# CH32X035 register map
Vendor: WCH Ltd.; File version: 1.2
Registers are 32-bit, read-write, reset 0x0 unless marked. A register's access mark holds for its fields unless they carry their own. Offsets are from the block's base; [hi:lo] are bit positions.

## IWDG — Independent watchdog
Base 0x40003000
0x00 CTLR 16-bit wo — Key register (IWDG_CTLR)
  [15:0] KEY — Key value
0x04 PSCR 16-bit — Prescaler register (IWDG_PSCR)
  [2:0] PR — Prescaler divider
0x08 RLDR 16-bit reset 0xFFF — Reload register (IWDG_RLDR)
  [11:0] RL — Watchdog counter reload value
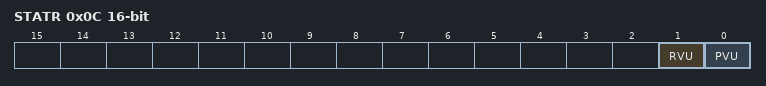
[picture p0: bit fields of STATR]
0x0C STATR 16-bit ro — Status register (IWDG_SR)
  [1] RVU — Watchdog counter reload value update
  [0] PVU — Watchdog prescaler value update

## WWDG — Window watchdog
Base 0x40002C00
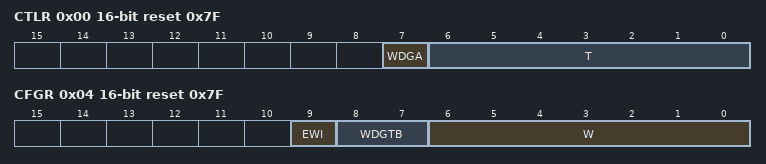
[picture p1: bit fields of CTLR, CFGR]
0x00 CTLR 16-bit reset 0x7F — Control register (WWDG_CR)
  [7] WDGA — Activation bit
  [6:0] T — 7-bit counter (MSB to LSB)
0x04 CFGR 16-bit access per field reset 0x7F — Configuration register (WWDG_CFR)
  [9] EWI read/set — Early Wakeup Interrupt
  [8:7] WDGTB rw — Timer Base
  [6:0] W rw — 7-bit window value
0x08 STATR 16-bit read/clear — Status register (WWDG_SR)
  [0] EWIF — Early Wakeup Interrupt Flag

## TIM3 — General purpose timer
Base 0x40000400
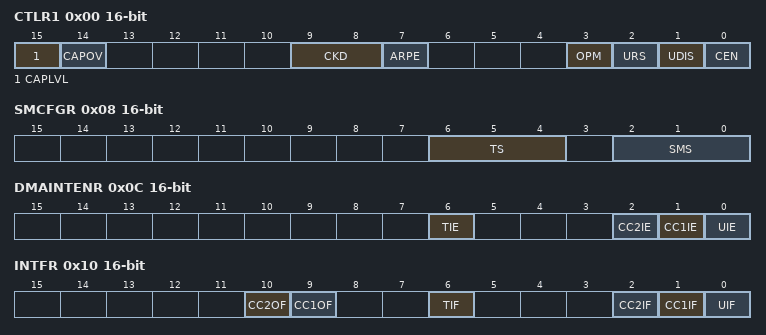
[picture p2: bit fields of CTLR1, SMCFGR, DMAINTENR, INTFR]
0x00 CTLR1 16-bit — control register 1
  [15] CAPLVL
  [14] CAPOV
  [9:8] CKD — Clock division
  [7] ARPE — Auto-reload preload enable
  [3] OPM — One-pulse mode
  [2] URS — Update request source
  [1] UDIS — Update disable
  [0] CEN — Counter enable
0x08 SMCFGR 16-bit — slave mode control register
  [6:4] TS — Trigger selection
  [2:0] SMS — Slave mode selection
0x0C DMAINTENR 16-bit — DMA/Interrupt enable register
  [6] TIE — Trigger interrupt enable
  [2] CC2IE — Capture/Compare 2 interrupt enable
  [1] CC1IE — Capture/Compare 1 interrupt enable
  [0] UIE — Update interrupt enable
0x10 INTFR 16-bit wo — status register
  [10] CC2OF — Capture/compare 2 overcapture flag
  [9] CC1OF — Capture/Compare 1 overcapture flag
  [6] TIF — Trigger interrupt flag
  [2] CC2IF — Capture/Compare 2 interrupt flag
  [1] CC1IF — Capture/compare 1 interrupt flag
  [0] UIF — Update interrupt flag
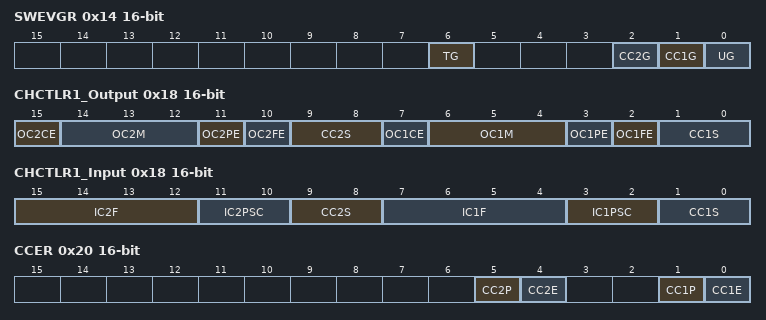
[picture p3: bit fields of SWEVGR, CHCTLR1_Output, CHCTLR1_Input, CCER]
0x14 SWEVGR 16-bit wo — event generation register
  [6] TG — Trigger generation
  [2] CC2G — Capture/compare 2 generation
  [1] CC1G — Capture/compare 1 generation
  [0] UG — Update generation
0x18 CHCTLR1_Output 16-bit — capture/compare mode register 1 (output mode)
  [15] OC2CE — Output compare 2 clear enable
  [14:12] OC2M — Output compare 2 mode
  [11] OC2PE — Output compare 2 preload enable
  [10] OC2FE — Output compare 2 fast enable
  [9:8] CC2S — Capture/Compare 2 selection
  [7] OC1CE — Output compare 1 clear enable
  [6:4] OC1M — Output compare 1 mode
  [3] OC1PE — Output compare 1 preload enable
  [2] OC1FE — Output compare 1 fast enable
  [1:0] CC1S — Capture/Compare 1 selection
0x18 CHCTLR1_Input 16-bit (alternate view of CHCTLR1_Output) — capture/compare mode register 1 (input mode)
  [15:12] IC2F — Input capture 2 filter
  [11:10] IC2PSC — Input capture 2 prescaler
  [9:8] CC2S — Capture/compare 2 selection
  [7:4] IC1F — Input capture 1 filter
  [3:2] IC1PSC — Input capture 1 prescaler
  [1:0] CC1S — Capture/Compare 1 selection
0x20 CCER 16-bit — capture/compare enable register
  [5] CC2P — Capture/Compare 2 output Polarity
  [4] CC2E — Capture/Compare 2 output enable
  [1] CC1P — Capture/Compare 1 output Polarity
  [0] CC1E — Capture/Compare 1 output enable
0x24 CNT 16-bit — counter
  [15:0] CNT — counter value
0x28 PSC 16-bit — prescaler
  [15:0] PSC — Prescaler value
0x2C ATRLR 16-bit reset 0xFFFF — auto-reload register
  [15:0] ATRLR — Auto-reload value
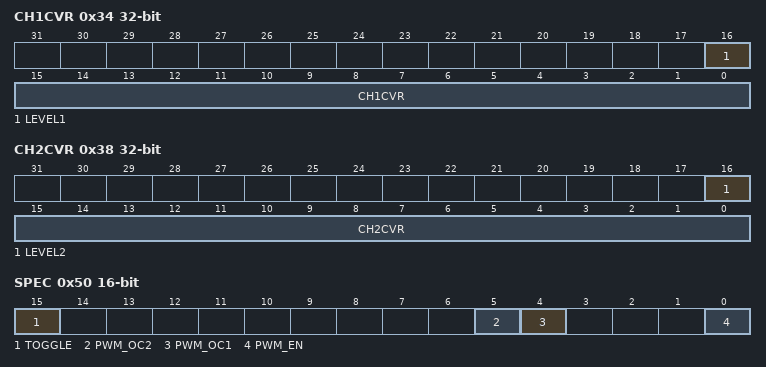
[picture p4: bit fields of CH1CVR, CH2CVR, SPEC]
0x34 CH1CVR access per field — capture/compare register 1
  [16] LEVEL1 ro — Level indicating bit
  [15:0] CH1CVR rw — Capture/Compare 1 value
0x38 CH2CVR access per field — capture/compare register 2
  [16] LEVEL2 ro — Level indicating bit
  [15:0] CH2CVR rw — Capture/Compare 2 value
0x50 SPEC 16-bit access per field
  [15] TOGGLE ro, [5] PWM_OC2 rw, [4] PWM_OC1 rw, [0] PWM_EN rw
